# RT584ZCM33 register map
Series: ARMv8-M Mainline; File version: 1.0
CPU: CM33 r0p0, little endian, MPU, no FPU, VTOR, 3 interrupt priority bits
Registers are 32-bit, read-write, reset 0x0 unless marked. A register's access mark holds for its fields unless they carry their own. Offsets are from the block's base; [hi:lo] are bit positions; {n}, {i} and the like mark numbered series.

## UART0_Non-Secure — UART0 Non-Secure Register block
Base 0x40012000
Same registers: UART1_Non-Secure 0x40013000, UART2_Non-Secure 0x40025000, UART0_Secure 0x50012000, UART1_Secure 0x50013000, UART2_Secure 0x50025000
0x00 UART_THRRBR_REG — UART Transmit and Receive Buffer
  [7:0] RBR ro — Received Data
  [7:0] THR wo — Data To be transmitted
0x04 UART_IER_REG — uart ier
  [6:0] intr_en — [0] Enable Received Data Available Interrupt. [1] Enable Transmitter Holding Register Interrupt. [2] Enable Receiver Line Status Interrupt. [3] Enable MODEM Status Interrupt. [4] Enable Received Data timeout Interrupt. [5] Enable DMA RX Interrupt [6] Enable DMA TX Interrupt
    0=B_0_to_6 ([0] Enable Received Data Available Interrupt. [1] Enable Transmitter Holding Register Interrupt. [2] Enable Receiver Line Status Interrupt. [3] Enable MODEM Status Interrupt. [4] Enable Received Data timeout Interrupt. [5] Enable DMA RX Interrupt [6] Enable DMA TX Interrupt)
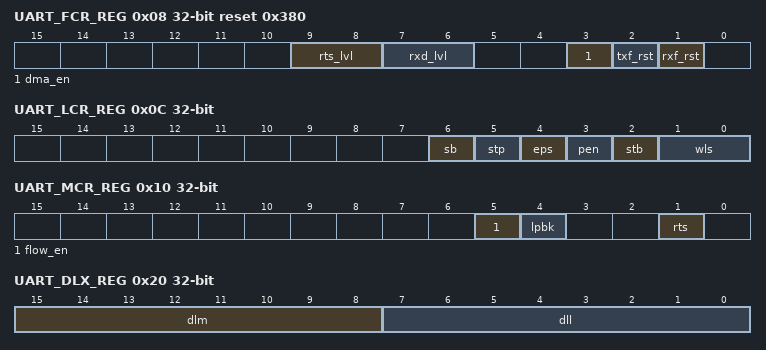
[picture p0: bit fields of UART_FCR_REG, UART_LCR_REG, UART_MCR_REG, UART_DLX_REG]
0x08 UART_FCR_REG reset 0x380 — uart fcr
  [9:8] rts_lvl — RTS trigger level. When number of data in rx fifo equal to or exceed this level, de-assert pin RTSn (set RTSn=1). The RSTn will assert when rx fifo is empty. 0: 1 byte 1: 4 byte 2: 8 byte 3: 14 byte
    0=B_8_to_9_ITEM0 (1 byte); 1=B_8_to_9_ITEM1 (4 byte); 2=B_8_to_9_ITEM2 (8 byte); 3=B_8_to_9_ITEM3 (14 byte)
  [7:6] rxd_lvl — Receiver Trigger Level. When number of data in rx fifo equal to or exceed this level, assert rda_intr (set rda_intr=1) 0: 1 byte 1: 4 byte 2: 8 byte 3: 14 byte
    0=B_6_to_7_ITEM0 (1 byte); 1=B_6_to_7_ITEM1 (4 byte); 2=B_6_to_7_ITEM2 (8 byte); 3=B_6_to_7_ITEM3 (14 byte)
  [3] dma_en — DMA enable
    0=B_3 (DMA enable)
  [2] txf_rst wo — Transmit FIFO reset (self-clearing).
    0=B_2 (Transmit FIFO reset (self-clearing).)
  [1] rxf_rst wo — Receive FIFO reset (self-clearing).
    0=B_1 (Receive FIFO reset (self-clearing).)
0x0C UART_LCR_REG — uart lcr
  [6] sb — Set Break.
    0=B_6 (Set Break.)
  [5] stp — Stick Parity.
    0=B_5 (Stick Parity.)
  [4] eps — Even Parity Select.
    0=B_4 (Even Parity Select.)
  [3] pen — Parity Enable.
    0=B_3 (Parity Enable.)
  [2] stb — Number of Stop Bits 0: 1 stop bit. 1: 2 stop bits
    0=B_2_ITEM0 (1 stop bit.); 1=B_2_ITEM1 (2 stop bits)
  [1:0] wls — Word Length Select. 0: 5-bit data 1: 6-bit data 2: 7-bit data 3: 8-bit data
    {v}=B_0_to_1_ITEM{v} ({v+5}-bit data) (v=0..3)
0x10 UART_MCR_REG — uart mcr
  [5] flow_en — Auto Flow Control Enable.
    0=B_5 (Auto Flow Control Enable.)
  [4] lpbk — Loopback mode select.
    0=B_4 (Loopback mode select.)
  [1] rts — Request to Send 0: RTSn=1 1: RTSn=0
    0=B_1_ITEM0 (RTSn=1); 1=B_1_ITEM1 (RTSn=0)
0x14 UART_LSR_REG — uart lsr
  [6] temt ro — Transmitter Empty. The status indicate tx fifo is empty and transmission is done.
    0=B_6 (Transmitter Empty. The status indicate tx fifo is empty and transmission is done.)
  [5] thre ro — Transmitter Holding Register Empty. The status indicate tx fifo is empty. Write thr to clear.
    0=B_5 (Transmitter Holding Register Empty. The status indicate tx fifo is empty. Write thr to clear.)
  [4] bi ro — Break Interrupt. Write 1 to clear.
    0=B_4 (Break Interrupt. Write 1 to clear.)
  [4] bi_clr wo — Write 1 to clear bi.
    0=B_4 (Write 1 to clear bi.)
  [3] fe ro — Framing Error. Write 1 to clear.
    0=B_3 (Framing Error. Write 1 to clear.)
  [3] fe_clr wo — Write 1 to clear fe.
    0=B_3 (Write 1 to clear fe.)
  [2] pe ro — Parity Error. Write 1 to clear.
    0=B_2 (Parity Error. Write 1 to clear.)
  [2] pe_clr wo — Write 1 to clear pe.
    0=B_2 (Write 1 to clear pe.)
  [1] oe ro — Overrun Error. Write 1 to clear.
    0=B_1 (Overrun Error. Write 1 to clear.)
  [1] oe_clr wo — Write 1 to clear oe.
    0=B_1 (Write 1 to clear oe.)
  [0] dr ro — Data Ready. It's 1'b1 when rx fifo is not empty. Read rbr until rx fifo is empty to clear.
    0=B_0 (Data Ready. It's 1'b1 when rx fifo is not empty. Read rbr until rx fifo is empty to clear.)
0x18 UART_MSR_REG — uart msr
  [4] cts ro — Clear To Send.
    0=B_4 (Clear To Send.)
  [0] dcts ro — Delta Clear To Send. Write 1 to clear.
    0=B_0 (Delta Clear To Send. Write 1 to clear.)
  [0] dcts_clr wo — Write 1 to clear dcts.
    0=B_0 (Write 1 to clear dcts.)
0x1C UART_ISR_REG — uart isr
  [6] dma_tx_intr ro — Interrupt status for DMA TX. Write 1 to clear.
    0=B_6 (Interrupt status for DMA TX. Write 1 to clear.)
  [6] dma_tx_clr wo — Write 1 to clear dma_tx_intr.
    0=B_6 (Write 1 to clear dma_tx_intr.)
  [5] dma_rx_intr ro — Interrupt status for DMA RX. Write 1 to clear.
    0=B_5 (Interrupt status for DMA RX. Write 1 to clear.)
  [5] dma_rx_clr wo — Write 1 to clear dma_rx_intr.
    0=B_5 (Write 1 to clear dma_rx_intr.)
  [4] rxto_intr ro — Assert when rx fifo is not empty and no access of fifo for 4 bytes long. Write 1 to clear.
    0=B_4 (Assert when rx fifo is not empty and no access of fifo for 4 bytes long. Write 1 to clear.)
  [4] rxto_clr wo — Write 1 to clear rxto_intr.
    0=B_4 (Write 1 to clear rxto_intr.)
  [3] msr_intr ro — Assert when pin CTSn change. This bit reflects dcts. Clear dcts to clear msr_intr.
    0=B_3 (Assert when pin CTSn change. This bit reflects dcts. Clear dcts to clear msr_intr.)
  [2] lsr_intr ro — Assert when either oe/pe/fe/bi is 1. Clear all of oe/pe/fe/bi to clear lsr_intr.
    0=B_2 (Assert when either oe/pe/fe/bi is 1. Clear all of oe/pe/fe/bi to clear lsr_intr.)
  [1] thre_intr ro — Assert when thre from 0 to 1. Write 1 to clear.
    0=B_1 (Assert when thre from 0 to 1. Write 1 to clear.)
  [1] thre_clr wo — Write 1 to clear thre_intr.
    0=B_1 (Write 1 to clear thre_intr.)
  [0] rda_intr ro — Assert when number of data in rx fifo equal to or exceed rxd_lvl. Write 1 to clear.
    0=B_0 (Assert when number of data in rx fifo equal to or exceed rxd_lvl. Write 1 to clear.)
  [0] rda_clr wo — Write 1 to clear rda_intr.
    0=B_0 (Write 1 to clear rda_intr.)
0x20 UART_DLX_REG — uart dlx
  [15:8] dlm — Most significant byte, Divisor Latch [15:8] for input to baud rate generator.
    0=B_8_to_15 (Most significant byte, Divisor Latch [15:8] for input to baud rate generator.)
  [7:0] dll — Least significant byte, Divisor Latch [7:0] for input to baud rate generator.
    0=B_0_to_7 (Least significant byte, Divisor Latch [7:0] for input to baud rate generator.)
0x24 UART_FDL_REG — uart fdl
  [7:0] frac_dlx — Fraction Divisor Latch According to the value of Divisor_fraction, if 0, set to 0000_0000 if 1, set to 0001_0000 if 2, set to 0001_1000 if 3, set to 0011_1000 if 4, set to 0011_1100 if 5, set to 0111_1100 if 6, set to 0111_1110 if 7, set to 0111_1111 if 8, set to 0000_0000
    0=B_0_to_7 (Fraction Divisor Latch According to the value of Divisor_fraction, if 0, set to 0000_0000 if 1, set to 0001_0000 if 2, set to 0001_1000 if 3, set to 0011_1000 if 4, set to 0011_1100 if 5, set to 0111_1100 if 6, set to 0111_1110 if 7, set to 0111_1111 if 8, set to 0000_0000)
0x28 UART_LSM_REG — uart lsm
  [0] lsm — Low speed mode. Oversampling is 4x instead of 8x when lsm=1
    0=B_0 (Low speed mode. Oversampling is 4x instead of 8x when lsm=1)
0x2C UART_WAKE_EN_REG — uart wake en
  [0] uart_sleep_wake_en — wake en
    0=B_0 (wake en)
0x30 UART_EN_REG — uart en
  [0] uart_enable — Set 1 to start UART after all above setting is ready.
    0=B_0 (Set 1 to start UART after all above setting is ready.)
0x34 DMARCVSTARTADR_REG — Start address of receive buffer in RAM for DMA.
0x38 DMARCVBYTECNT_REG — dmarcvbytecnt
  [15:0] dma_rx_length — Transfer byte length of receive buffer in RAM for DMA.
0x3C DMAXMTSTARTADR_REG — Start address of transmit buffer in RAM for DMA.
0x40 DMAXMTBYTECNT_REG — dmaxmtbytecnt
  [15:0] dma_tx_length — Transfer byte length of transmit buffer in RAM for DMA.
0x44 DMARCVREMAINCNT_REG ro — dmarcvremaincnt
  [15:0] dma_rx_remain_len — Remain byte length of receive buffer for DmaRcvByteCnt setting.
0x48 DMAXMTREMAINCNT_REG ro — dmaxmtremaincnt
  [15:0] dma_tx_remain_len — Remain byte length of transmit buffer for DmaXmtByteCnt setting.
0x4C DMARCVENABLE_REG — dmarcvenable
  [0] dma_rx_enable — Enable receive DMA channel. Write 0 for completion or abort.
    0=B_0 (Enable receive DMA channel. Write 0 for completion or abort.)
0x50 DMAXMTENABLE_REG — dmaxmtenable
  [0] dma_tx_enable — Enable transmit DMA channel. Write 0 for completion or abort.
    0=B_0 (Enable transmit DMA channel. Write 0 for completion or abort.)
